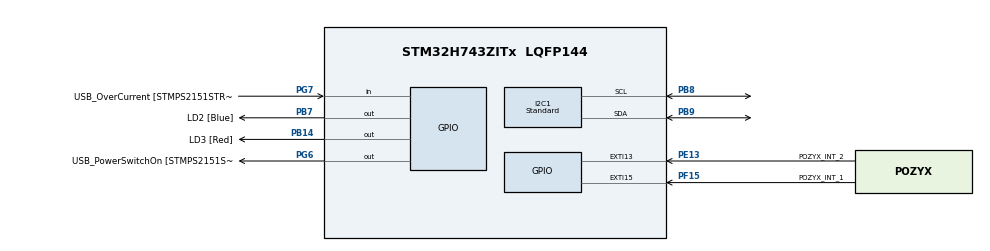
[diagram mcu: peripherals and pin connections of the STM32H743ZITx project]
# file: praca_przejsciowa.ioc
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FREERTOS.Tasks01=defaultTask,0,128,StartDefaultTask,Default,NULL
I2C1.I2C_Speed_Mode=I2C_Standard
I2C1.Timing=0x10909CEC
Mcu.Family=STM32H7
Mcu.Name=STM32H743ZITx
Mcu.Package=LQFP144
NVIC.EXTI15_10_IRQn=true\:5\:0\:false\:true\:true\:1\:true\:true
NVIC.PriorityGroup=NVIC_PRIORITYGROUP_4
NVIC.TIM1_UP_IRQn=true\:0\:0\:false\:false\:true\:false\:false
NVIC.TimeBase=TIM1_UP_IRQn
NVIC.TimeBaseIP=TIM1
PA1.GPIO_Label=RMII_REF_CLK
PA1.Signal=ETH_REF_CLK
PA10.GPIO_Label=USB_ID
PA10.Signal=USB_OTG_FS_ID
PA11.GPIO_Label=USB_DM
PA11.Signal=USB_OTG_FS_DM
PA12.GPIO_Label=USB_DP
PA12.Signal=USB_OTG_FS_DP
PA13.GPIO_Label=TMS
PA13.Signal=SYS_JTMS-SWDIO
PA14.GPIO_Label=TCK
PA14.Signal=SYS_JTCK-SWCLK
PA2.GPIO_Label=RMII_MDIO
PA2.Signal=ETH_MDIO
PA7.GPIO_Label=RMII_CRS_DV
PA7.Signal=ETH_CRS_DV
PA8.GPIO_Label=USB_SOF [TP1]
PA8.Signal=USB_OTG_FS_SOF
PA9.GPIO_Label=USB_VBUS
PA9.Signal=USB_OTG_FS_VBUS
PB13.GPIO_Label=RMII_TXD1
PB13.Signal=ETH_TXD1
PB14.GPIO_Label=LD3 [Red]
PB14.Signal=GPIO_Output
PB3.GPIO_Label=SWO
PB3.Signal=SYS_JTDO-SWO
PB7.GPIO_Label=LD2 [Blue]
PB7.Signal=GPIO_Output
PB8.GPIO_PuPd=GPIO_PULLUP
PB8.GPIO_Speed=GPIO_SPEED_FREQ_HIGH
PB8.Mode=I2C
PB8.Signal=I2C1_SCL
PB9.GPIO_PuPd=GPIO_PULLUP
PB9.GPIO_Speed=GPIO_SPEED_FREQ_HIGH
PB9.Mode=I2C
PB9.Signal=I2C1_SDA
PC1.GPIO_Label=RMII_MDC
PC1.Signal=ETH_MDC
PC14-OSC32_IN.Signal=RCC_OSC32_IN
PC15-OSC32_OUT.Signal=RCC_OSC32_OUT
PC4.GPIO_Label=RMII_RXD0
PC4.Signal=ETH_RXD0
PC5.GPIO_Label=RMII_RXD1
PC5.Signal=ETH_RXD1
PD8.GPIO_Label=STLK_RX [STM32F103CBT6_PA3]
PD8.Signal=USART3_TX
PD9.GPIO_Label=STLK_TX [STM32F103CBT6_PA2]
PD9.Signal=USART3_RX
PE13.GPIO_Label=POZYX_INT_2
PE13.Signal=GPXTI13
PE15.Signal=EVENTOUT
PF15.GPIO_Label=POZYX_INT_1
PF15.Signal=GPXTI15
PG11.GPIO_Label=RMII_TX_EN
PG11.Signal=ETH_TX_EN
PG13.GPIO_Label=RMII_TXD0
PG13.Signal=ETH_TXD0
PG6.GPIO_Label=USB_PowerSwitchOn [STMPS2151STR_EN]
PG6.Signal=GPIO_Output
PG7.GPIO_Label=USB_OverCurrent [STMPS2151STR_FAULT]
PG7.Signal=GPIO_Input
PH0-OSC_IN.GPIO_Label=MCO
PH0-OSC_IN.Signal=RCC_OSC_IN
ProjectManager.HeapSize=0x200
ProjectManager.StackSize=0x400
ProjectManager.TargetToolchain=TrueSTUDIO
RCC.48MHZClocksFreq_Value=24000000
RCC.ADCFreq_Value=129000000
RCC.AHBFreq_Value=216000000
RCC.APB1CLKDivider=RCC_HCLK_DIV4
RCC.APB1Freq_Value=80000000
RCC.APB1TimFreq_Value=108000000
RCC.APB2CLKDivider=RCC_HCLK_DIV2
RCC.APB2Freq_Value=80000000
RCC.APB2TimFreq_Value=216000000
RCC.APB3Freq_Value=80000000
RCC.APB4Freq_Value=80000000
RCC.CortexFreq_Value=80000000
RCC.DIVM1=4
RCC.DIVN1=10
RCC.DIVQ1=4
RCC.HCLKFreq_Value=80000000
RCC.HSE_VALUE=8000000
RCC.HSI_VALUE=64000000
RCC.PLLM=25
RCC.PLLMUL=RCC_PLL_MUL9
RCC.PLLN=432
RCC.PLLQ=9
RCC.PRESCALERUSB=RCC_USBCLKSOURCE_PLL_DIV1_5
RCC.SYSCLKFreq_VALUE=80000000
RCC.SYSCLKSource=RCC_SYSCLKSOURCE_PLLCLK
RCC.SYSCLKSourceVirtual=RCC_SYSCLKSOURCE_PLLCLK
RCC.USBFreq_Value=40000000
RCC.VCOOutputFreq_Value=432000000
VP_FREERTOS_VS_ENABLE.Mode=Enabled
VP_SYS_VS_tim1.Mode=TIM1
board=NUCLEO-H743ZI

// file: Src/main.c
/**
  ******************************************************************************
  * @file           : main.c
  * @brief          : Main program body
  ******************************************************************************
  * This notice applies to any and all portions of this file
  * that are not between comment pairs USER CODE BEGIN and
  * USER CODE END. Other portions of this file, whether
  * inserted by the user or by software development tools
  * are owned by their respective copyright owners.
  *
  * Copyright (c) 2019 STMicroelectronics International N.V.
  * All rights reserved.
  *
  * Redistribution and use in source and binary forms, with or without
  * modification, are permitted, provided that the following conditions are met:
  *
  * 1. Redistribution of source code must retain the above copyright notice,
  *    this list of conditions and the following disclaimer.
  * 2. Redistributions in binary form must reproduce the above copyright notice,
  *    this list of conditions and the following disclaimer in the documentation
  *    and/or other materials provided with the distribution.
  * 3. Neither the name of STMicroelectronics nor the names of other
  *    contributors to this software may be used to endorse or promote products
  *    derived from this software without specific written permission.
  * 4. This software, including modifications and/or derivative works of this
  *    software, must execute solely and exclusively on microcontroller or
  *    microprocessor devices manufactured by or for STMicroelectronics.
  * 5. Redistribution and use of this software other than as permitted under
  *    this license is void and will automatically terminate your rights under
  *    this license.
  *
  * THIS SOFTWARE IS PROVIDED BY STMICROELECTRONICS AND CONTRIBUTORS "AS IS"
  * AND ANY EXPRESS, IMPLIED OR STATUTORY WARRANTIES, INCLUDING, BUT NOT
  * LIMITED TO, THE IMPLIED WARRANTIES OF MERCHANTABILITY, FITNESS FOR A
  * PARTICULAR PURPOSE AND NON-INFRINGEMENT OF THIRD PARTY INTELLECTUAL PROPERTY
  * RIGHTS ARE DISCLAIMED TO THE FULLEST EXTENT PERMITTED BY LAW. IN NO EVENT
  * SHALL STMICROELECTRONICS OR CONTRIBUTORS BE LIABLE FOR ANY DIRECT, INDIRECT,
  * INCIDENTAL, SPECIAL, EXEMPLARY, OR CONSEQUENTIAL DAMAGES (INCLUDING, BUT NOT
  * LIMITED TO, PROCUREMENT OF SUBSTITUTE GOODS OR SERVICES; LOSS OF USE, DATA,
  * OR PROFITS; OR BUSINESS INTERRUPTION) HOWEVER CAUSED AND ON ANY THEORY OF
  * LIABILITY, WHETHER IN CONTRACT, STRICT LIABILITY, OR TORT (INCLUDING
  * NEGLIGENCE OR OTHERWISE) ARISING IN ANY WAY OUT OF THE USE OF THIS SOFTWARE,
  * EVEN IF ADVISED OF THE POSSIBILITY OF SUCH DAMAGE.
  *
  ******************************************************************************
  */
#include "main.h"
#include "stm32h7xx_hal.h"
#include "cmsis_os.h"
#include "i2c.h"
#include "gpio.h"

/* USER CODE BEGIN PV */
/* Private variables ---------------------------------------------------------*/

/* USER CODE END PV */

void SystemClock_Config(void);
void MX_FREERTOS_Init(void);
static void MX_NVIC_Init(void);

/* USER CODE BEGIN PFP */
/* Private function prototypes -----------------------------------------------*/
/* USER CODE END PFP */

int main(void)
{

  /* MCU Configuration----------------------------------------------------------*/

  /* Reset of all peripherals, Initializes the Flash interface and the Systick. */
  HAL_Init();

  /* Configure the system clock */
  SystemClock_Config();

  /* Initialize all configured peripherals */
  MX_GPIO_Init();
  MX_I2C1_Init();

  /* Initialize interrupts */
  MX_NVIC_Init();

  /* Call init function for freertos objects (in freertos.c) */
  MX_FREERTOS_Init();

  /* Start scheduler */
  osKernelStart();

  /* We should never get here as control is now taken by the scheduler */

  /* Infinite loop */
  while (1)
  {

  }

}

void SystemClock_Config(void)
{

  RCC_OscInitTypeDef RCC_OscInitStruct;
  RCC_ClkInitTypeDef RCC_ClkInitStruct;
  RCC_PeriphCLKInitTypeDef PeriphClkInitStruct;

    /**Supply configuration update enable
    */
  MODIFY_REG(PWR->CR3, PWR_CR3_SCUEN, 0);

    /**Configure the main internal regulator output voltage
    */
  __HAL_PWR_VOLTAGESCALING_CONFIG(PWR_REGULATOR_VOLTAGE_SCALE3);

  while ((PWR->D3CR & (PWR_D3CR_VOSRDY)) != PWR_D3CR_VOSRDY)
  {

  }
    /**Initializes the CPU, AHB and APB busses clocks
    */
  RCC_OscInitStruct.OscillatorType = RCC_OSCILLATORTYPE_HSI;
  RCC_OscInitStruct.HSIState = RCC_HSI_DIV1;
  RCC_OscInitStruct.HSICalibrationValue = 16;
  RCC_OscInitStruct.PLL.PLLState = RCC_PLL_ON;
  RCC_OscInitStruct.PLL.PLLSource = RCC_PLLSOURCE_HSI;
  RCC_OscInitStruct.PLL.PLLM = 4;
  RCC_OscInitStruct.PLL.PLLN = 10;
  RCC_OscInitStruct.PLL.PLLP = 2;
  RCC_OscInitStruct.PLL.PLLQ = 4;
  RCC_OscInitStruct.PLL.PLLR = 2;
  RCC_OscInitStruct.PLL.PLLRGE = RCC_PLL1VCIRANGE_3;
  RCC_OscInitStruct.PLL.PLLVCOSEL = RCC_PLL1VCOMEDIUM;
  RCC_OscInitStruct.PLL.PLLFRACN = 0;
  if (HAL_RCC_OscConfig(&RCC_OscInitStruct) != HAL_OK)
  {
    _Error_Handler(__FILE__, __LINE__);
  }

    /**Initializes the CPU, AHB and APB busses clocks
    */
  RCC_ClkInitStruct.ClockType = RCC_CLOCKTYPE_HCLK|RCC_CLOCKTYPE_SYSCLK
                              |RCC_CLOCKTYPE_PCLK1|RCC_CLOCKTYPE_PCLK2
                              |RCC_CLOCKTYPE_D3PCLK1|RCC_CLOCKTYPE_D1PCLK1;
  RCC_ClkInitStruct.SYSCLKSource = RCC_SYSCLKSOURCE_PLLCLK;
  RCC_ClkInitStruct.SYSCLKDivider = RCC_SYSCLK_DIV1;
  RCC_ClkInitStruct.AHBCLKDivider = RCC_HCLK_DIV1;
  RCC_ClkInitStruct.APB3CLKDivider = RCC_APB3_DIV1;
  RCC_ClkInitStruct.APB1CLKDivider = RCC_APB1_DIV1;
  RCC_ClkInitStruct.APB2CLKDivider = RCC_APB2_DIV1;
  RCC_ClkInitStruct.APB4CLKDivider = RCC_APB4_DIV1;

  if (HAL_RCC_ClockConfig(&RCC_ClkInitStruct, FLASH_LATENCY_1) != HAL_OK)
  {
    _Error_Handler(__FILE__, __LINE__);
  }

  PeriphClkInitStruct.PeriphClockSelection = RCC_PERIPHCLK_I2C1;
  PeriphClkInitStruct.I2c123ClockSelection = RCC_I2C123CLKSOURCE_D2PCLK1;
  if (HAL_RCCEx_PeriphCLKConfig(&PeriphClkInitStruct) != HAL_OK)
  {
    _Error_Handler(__FILE__, __LINE__);
  }

    /**Configure the Systick interrupt time
    */
  HAL_SYSTICK_Config(SystemCoreClock/1000);

    /**Configure the Systick
    */
  HAL_SYSTICK_CLKSourceConfig(SYSTICK_CLKSOURCE_HCLK);

  /* SysTick_IRQn interrupt configuration */
  HAL_NVIC_SetPriority(SysTick_IRQn, 15, 0);
}

/**
  * @brief NVIC Configuration.
  * @retval None
  */
static void MX_NVIC_Init(void)
{
  /* EXTI15_10_IRQn interrupt configuration */
  HAL_NVIC_SetPriority(EXTI15_10_IRQn, 5, 0);
  HAL_NVIC_EnableIRQ(EXTI15_10_IRQn);
}

void HAL_TIM_PeriodElapsedCallback(TIM_HandleTypeDef *htim)
{
  if (htim->Instance == TIM1) {
    HAL_IncTick();
  }
}

void _Error_Handler(char *file, int line)
{
  while(1)
  {
  }
}

/************************ (C) COPYRIGHT STMicroelectronics *****END OF FILE****/

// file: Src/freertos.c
/* USER CODE BEGIN Header */
/**
  ******************************************************************************
  * File Name          : freertos.c
  * Description        : Code for freertos applications
  ******************************************************************************
  * This notice applies to any and all portions of this file
  * that are not between comment pairs USER CODE BEGIN and
  * USER CODE END. Other portions of this file, whether
  * inserted by the user or by software development tools
  * are owned by their respective copyright owners.
  *
  * Copyright (c) 2019 STMicroelectronics International N.V.
  * All rights reserved.
  *
  * Redistribution and use in source and binary forms, with or without
  * modification, are permitted, provided that the following conditions are met:
  *
  * 1. Redistribution of source code must retain the above copyright notice,
  *    this list of conditions and the following disclaimer.
  * 2. Redistributions in binary form must reproduce the above copyright notice,
  *    this list of conditions and the following disclaimer in the documentation
  *    and/or other materials provided with the distribution.
  * 3. Neither the name of STMicroelectronics nor the names of other
  *    contributors to this software may be used to endorse or promote products
  *    derived from this software without specific written permission.
  * 4. This software, including modifications and/or derivative works of this
  *    software, must execute solely and exclusively on microcontroller or
  *    microprocessor devices manufactured by or for STMicroelectronics.
  * 5. Redistribution and use of this software other than as permitted under
  *    this license is void and will automatically terminate your rights under
  *    this license.
  *
  * THIS SOFTWARE IS PROVIDED BY STMICROELECTRONICS AND CONTRIBUTORS "AS IS"
  * AND ANY EXPRESS, IMPLIED OR STATUTORY WARRANTIES, INCLUDING, BUT NOT
  * LIMITED TO, THE IMPLIED WARRANTIES OF MERCHANTABILITY, FITNESS FOR A
  * PARTICULAR PURPOSE AND NON-INFRINGEMENT OF THIRD PARTY INTELLECTUAL PROPERTY
  * RIGHTS ARE DISCLAIMED TO THE FULLEST EXTENT PERMITTED BY LAW. IN NO EVENT
  * SHALL STMICROELECTRONICS OR CONTRIBUTORS BE LIABLE FOR ANY DIRECT, INDIRECT,
  * INCIDENTAL, SPECIAL, EXEMPLARY, OR CONSEQUENTIAL DAMAGES (INCLUDING, BUT NOT
  * LIMITED TO, PROCUREMENT OF SUBSTITUTE GOODS OR SERVICES; LOSS OF USE, DATA,
  * OR PROFITS; OR BUSINESS INTERRUPTION) HOWEVER CAUSED AND ON ANY THEORY OF
  * LIABILITY, WHETHER IN CONTRACT, STRICT LIABILITY, OR TORT (INCLUDING
  * NEGLIGENCE OR OTHERWISE) ARISING IN ANY WAY OUT OF THE USE OF THIS SOFTWARE,
  * EVEN IF ADVISED OF THE POSSIBILITY OF SUCH DAMAGE.
  *
  ******************************************************************************
  */
/* USER CODE END Header */

#include "FreeRTOS.h"
#include "task.h"
#include "main.h"
#include "cmsis_os.h"

/* USER CODE BEGIN Includes */
#include "All.h"
/* USER CODE END Includes */

osThreadId defaultTaskHandle;

void StartDefaultTask(void const * argument);

void MX_FREERTOS_Init(void); /* (MISRA C 2004 rule 8.1) */

void MX_FREERTOS_Init(void) {

  /* Create the thread(s) */
  /* definition and creation of defaultTask */
  osThreadDef(defaultTask, StartDefaultTask, osPriorityNormal, 0, 128);
  defaultTaskHandle = osThreadCreate(osThread(defaultTask), NULL);

  /* USER CODE BEGIN RTOS_THREADS */
  All_begin();
  /* add threads, ... */
  /* USER CODE END RTOS_THREADS */

}

void StartDefaultTask(void const * argument)
{

  for(;;)
  {
    osDelay(1);
  }
}

/************************ (C) COPYRIGHT STMicroelectronics *****END OF FILE****/
